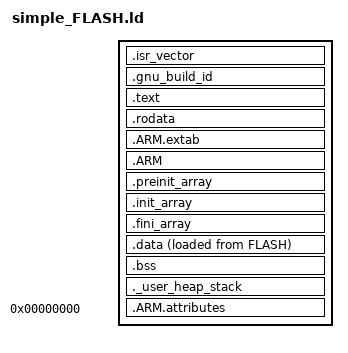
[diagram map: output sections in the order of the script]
/*
******************************************************************************
**

**  File        : LinkerScript.ld
**
**  Author		: Auto-generated by System Workbench for STM32
**
**  Abstract    : Linker script for STM32G474RETx series
**                512Kbytes FLASH and 128Kbytes RAM
**
**                Set heap size, stack size and stack location according
**                to application requirements.
**
**                Set memory bank area and size if external memory is used.
**
**  Target      : STMicroelectronics STM32
**
**  Distribution: The file is distributed “as is,” without any warranty
**                of any kind.
**
*****************************************************************************
** @attention
**
** <h2><center>&copy; COPYRIGHT(c) 2019 STMicroelectronics</center></h2>
**
** Redistribution and use in source and binary forms, with or without modification,
** are permitted provided that the following conditions are met:
**   1. Redistributions of source code must retain the above copyright notice,
**      this list of conditions and the following disclaimer.
**   2. Redistributions in binary form must reproduce the above copyright notice,
**      this list of conditions and the following disclaimer in the documentation
**      and/or other materials provided with the distribution.
**   3. Neither the name of STMicroelectronics nor the names of its contributors
**      may be used to endorse or promote products derived from this software
**      without specific prior written permission.
**
** THIS SOFTWARE IS PROVIDED BY THE COPYRIGHT HOLDERS AND CONTRIBUTORS "AS IS"
** AND ANY EXPRESS OR IMPLIED WARRANTIES, INCLUDING, BUT NOT LIMITED TO, THE
** IMPLIED WARRANTIES OF MERCHANTABILITY AND FITNESS FOR A PARTICULAR PURPOSE ARE
** DISCLAIMED. IN NO EVENT SHALL THE COPYRIGHT HOLDER OR CONTRIBUTORS BE LIABLE
** FOR ANY DIRECT, INDIRECT, INCIDENTAL, SPECIAL, EXEMPLARY, OR CONSEQUENTIAL
** DAMAGES (INCLUDING, BUT NOT LIMITED TO, PROCUREMENT OF SUBSTITUTE GOODS OR
** SERVICES; LOSS OF USE, DATA, OR PROFITS; OR BUSINESS INTERRUPTION) HOWEVER
** CAUSED AND ON ANY THEORY OF LIABILITY, WHETHER IN CONTRACT, STRICT LIABILITY,
** OR TORT (INCLUDING NEGLIGENCE OR OTHERWISE) ARISING IN ANY WAY OUT OF THE USE
** OF THIS SOFTWARE, EVEN IF ADVISED OF THE POSSIBILITY OF SUCH DAMAGE.
**
*****************************************************************************
*/

/* Entry Point */
ENTRY(Reset_Handler)

/* Highest address of the user mode stack */
_estack = ORIGIN(RAM) + LENGTH(RAM);    /* end of RAM */
/* Generate a link error if heap and stack don't fit into RAM */
_Min_Heap_Size = 0x200;      /* required amount of heap  */
_Min_Stack_Size = 0x400; /* required amount of stack */

/* firmware version and date */
%{JS: value('BuildSystem') === 'cmake' ? 'INCLUDE version.ld' : ''}
_version_major = DEFINED(_version_major) ? _version_major : 0x00;
_version_minor = DEFINED(_version_minor) ? _version_minor : 0x00;
_subversion = DEFINED(_subversion) ? _subversion : 0x0000;

_date = DEFINED(_date) ? _date : 0x00000000;
_time = DEFINED(_time) ? _time : 0x0000;

_git_size = DEFINED(_git_size) ? _git_size : 0x0000;

_projec_name_lo = DEFINED(_projec_name_lo) ? _projec_name_lo : 0x0000000000000000;
_projec_name_hi = DEFINED(_projec_name_hi) ? _projec_name_hi : 0x0000000000000000;

/* Specify the memory areas */
MEMORY
{
  RAM (xrw)      : ORIGIN = 0x20000000, LENGTH = %{SizeRAM}K
  FLASH (rx)      : ORIGIN = 0x8000000, LENGTH = %{SizeFlash}K
}

/* Define output sections */
SECTIONS
{
  /* The startup code goes first into FLASH */
  .isr_vector :
  {
    . = ALIGN(4);
    KEEP(*(.isr_vector)) /* Startup code */
    . = ALIGN(4);
  } >FLASH
  
  /* add build ID in flash NOTE use with flag -Wl,--build-id */
  .gnu_build_id :
  {
    /* https://interrupt.memfault.com/blog/gnu-build-id-for-firmware */
    PROVIDE(g_note_build_id = .);
    *(.note.gnu.build-id)
    /* ADD po version */
    PROVIDE(note_build_specification = .); /* set point build specification */
    BYTE(_version_major);
    BYTE(_version_minor);
    SHORT(_subversion);
    /* add date and time here for coumfitble access */
    QUAD(_projec_name_lo);
    QUAD(_projec_name_hi);
    LONG(_date);
    SHORT(_time);
    SHORT(_git_size);
    %{JS: value('BuildSystem') === 'cmake' ? '"git_comit.txt" /* TODO set as const or include from file */' : ''}
  } >FLASH

  /* The program code and other data goes into FLASH */
  .text :
  {
    . = ALIGN(4);
    *(.text)           /* .text sections (code) */
    *(.text*)          /* .text* sections (code) */
    *(.glue_7)         /* glue arm to thumb code */
    *(.glue_7t)        /* glue thumb to arm code */
    *(.eh_frame)

    KEEP (*(.init))
    KEEP (*(.fini))

    . = ALIGN(4);
    _etext = .;        /* define a global symbols at end of code */
  } >FLASH

  /* Constant data goes into FLASH */
  .rodata :
  {
    . = ALIGN(4);
    *(.rodata)         /* .rodata sections (constants, strings, etc.) */
    *(.rodata*)        /* .rodata* sections (constants, strings, etc.) */
    . = ALIGN(4);
  } >FLASH

  .ARM.extab   : { *(.ARM.extab* .gnu.linkonce.armextab.*) } >FLASH
  .ARM : {
    __exidx_start = .;
    *(.ARM.exidx*)
    __exidx_end = .;
  } >FLASH

  .preinit_array     :
  {
    PROVIDE_HIDDEN (__preinit_array_start = .);
    KEEP (*(.preinit_array*))
    PROVIDE_HIDDEN (__preinit_array_end = .);
  } >FLASH
  .init_array :
  {
    PROVIDE_HIDDEN (__init_array_start = .);
    KEEP (*(SORT(.init_array.*)))
    KEEP (*(.init_array*))
    PROVIDE_HIDDEN (__init_array_end = .);
  } >FLASH
  .fini_array :
  {
    PROVIDE_HIDDEN (__fini_array_start = .);
    KEEP (*(SORT(.fini_array.*)))
    KEEP (*(.fini_array*))
    PROVIDE_HIDDEN (__fini_array_end = .);
  } >FLASH

  /* used by the startup to initialize data */
  _sidata = LOADADDR(.data);

  /* Initialized data sections goes into RAM, load LMA copy after code */
  .data : 
  {
    . = ALIGN(4);
    _sdata = .;        /* create a global symbol at data start */
    *(.data)           /* .data sections */
    *(.data*)          /* .data* sections */

    . = ALIGN(4);
    _edata = .;        /* define a global symbol at data end */
  } >RAM AT> FLASH

  
  /* Uninitialized data section */
  . = ALIGN(4);
  .bss :
  {
    /* This is used by the startup in order to initialize the .bss secion */
    _sbss = .;         /* define a global symbol at bss start */
    __bss_start__ = _sbss;
    *(.bss)
    *(.bss*)
    *(COMMON)

    . = ALIGN(4);
    _ebss = .;         /* define a global symbol at bss end */
    __bss_end__ = _ebss;
  } >RAM

  /* User_heap_stack section, used to check that there is enough RAM left */
  ._user_heap_stack :
  {
    . = ALIGN(8);
    PROVIDE ( end = . );
    PROVIDE ( _end = . );
    . = . + _Min_Heap_Size;
    . = . + _Min_Stack_Size;
    . = ALIGN(8);
  } >RAM

  

  /* Remove information from the standard libraries */
  /DISCARD/ :
  {
    libc.a ( * )
    libm.a ( * )
    libgcc.a ( * )
  }

  .ARM.attributes 0 : { *(.ARM.attributes) }
}


